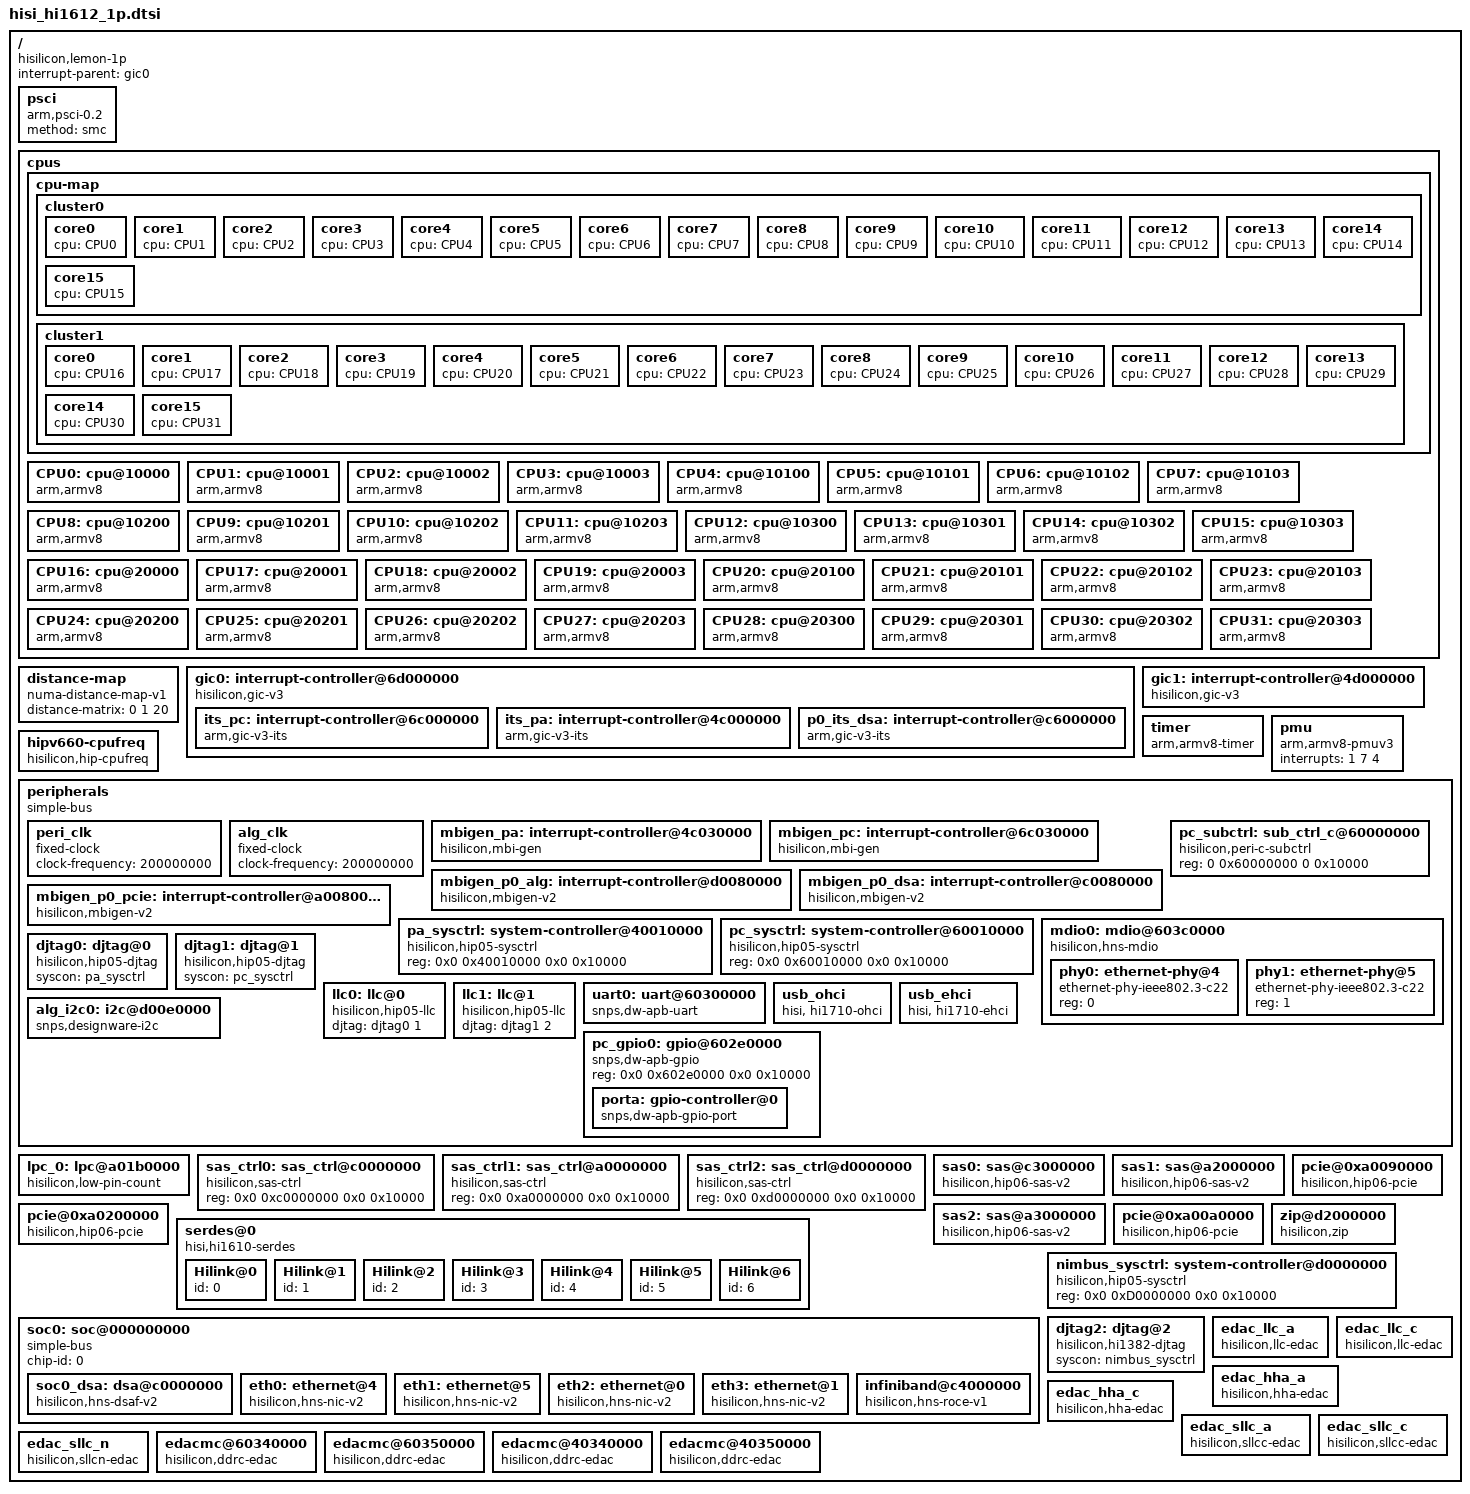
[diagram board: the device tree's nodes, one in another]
/**
 * dts file for IT lemon-1p Board(32cores)
 *
 * Copyright (C) 2014,2015 Hisilicon Ltd.
 *
 * This program is free software; you can redistribute it and/or modify
 * it under the terms of the GNU General Public License version 2 as
 * publishhed by the Free Software Foundation.
 *
 */

/ {
	#address-cells = <2>;
	#size-cells = <2>;
	compatible = "hisilicon,lemon-1p", "hisilicon,hi1612";
	interrupt-parent = <&gic0>;

	psci {
		compatible = "arm,psci-0.2";
		method = "smc";
	};

	cpus {
		#address-cells = <1>;
		#size-cells = <0>;

		cpu-map {
			cluster0 {
				core0 {
					cpu = <&CPU0>;
				};

				core1 {
					cpu = <&CPU1>;
				};

				core2 {
					cpu = <&CPU2>;
				};

				core3 {
					cpu = <&CPU3>;
				};

				core4 {
					cpu = <&CPU4>;
				};

				core5 {
					cpu = <&CPU5>;
				};

				core6 {
					cpu = <&CPU6>;
				};

				core7 {
					cpu = <&CPU7>;
				};

				core8 {
					cpu = <&CPU8>;
				};

				core9 {
					cpu = <&CPU9>;
				};

				core10 {
					cpu = <&CPU10>;
				};

				core11 {
					cpu = <&CPU11>;
				};

				core12 {
					cpu = <&CPU12>;
				};

				core13 {
					cpu = <&CPU13>;
				};

				core14 {
					cpu = <&CPU14>;
				};

				core15 {
					cpu = <&CPU15>;
				};
			};

			cluster1 {
				core0 {
					cpu = <&CPU16>;
				};

				core1 {
					cpu = <&CPU17>;
				};

				core2 {
					cpu = <&CPU18>;
				};

				core3 {
					cpu = <&CPU19>;
				};

				core4 {
					cpu = <&CPU20>;
				};

				core5 {
					cpu = <&CPU21>;
				};

				core6 {
					cpu = <&CPU22>;
				};

				core7 {
					cpu = <&CPU23>;
				};

				core8 {
					cpu = <&CPU24>;
				};

				core9 {
					cpu = <&CPU25>;
				};

				core10 {
					cpu = <&CPU26>;
				};

				core11 {
					cpu = <&CPU27>;
				};

				core12 {
					cpu = <&CPU28>;
				};

				core13 {
					cpu = <&CPU29>;
				};

				core14 {
					cpu = <&CPU30>;
				};

				core15 {
					cpu = <&CPU31>;
				};
			};
		};

		CPU0: cpu@10000 {
			device_type = "cpu";
			compatible = "arm,armv8";
			reg = <0x10000>;
			enable-method = "psci";
			numa-node-id = <0>;
		};

		CPU1: cpu@10001 {
			device_type = "cpu";
			compatible = "arm,armv8";
			reg = <0x10001>;
			enable-method = "psci";
			numa-node-id = <0>;
		};

		CPU2: cpu@10002 {
			device_type = "cpu";
			compatible = "arm,armv8";
			reg = <0x10002>;
			enable-method = "psci";
			numa-node-id = <0>;
		};

		CPU3: cpu@10003 {
			device_type = "cpu";
			compatible = "arm,armv8";
			reg = <0x10003>;
			enable-method = "psci";
			numa-node-id = <0>;
		};

		CPU4: cpu@10100 {
			device_type = "cpu";
			compatible = "arm,armv8";
			reg = <0x10100>;
			enable-method = "psci";
			numa-node-id = <0>;
		};

		CPU5: cpu@10101 {
			device_type = "cpu";
			compatible = "arm,armv8";
			reg = <0x10101>;
			enable-method = "psci";
			numa-node-id = <0>;
		};

		CPU6: cpu@10102 {
			device_type = "cpu";
			compatible = "arm,armv8";
			reg = <0x10102>;
			enable-method = "psci";
			numa-node-id = <0>;
		};

		CPU7: cpu@10103 {
			device_type = "cpu";
			compatible = "arm,armv8";
			reg = <0x10103>;
			enable-method = "psci";
			numa-node-id = <0>;
		};

		CPU8: cpu@10200 {
			device_type = "cpu";
			compatible = "arm,armv8";
			reg = <0x10200>;
			enable-method = "psci";
			numa-node-id = <0>;
		};

		CPU9: cpu@10201 {
			device_type = "cpu";
			compatible = "arm,armv8";
			reg = <0x10201>;
			enable-method = "psci";
			numa-node-id = <0>;
		};

		CPU10: cpu@10202 {
			device_type = "cpu";
			compatible = "arm,armv8";
			reg = <0x10202>;
			enable-method = "psci";
			numa-node-id = <0>;
		};

		CPU11: cpu@10203 {
			device_type = "cpu";
			compatible = "arm,armv8";
			reg = <0x10203>;
			enable-method = "psci";
			numa-node-id = <0>;
		};

		CPU12: cpu@10300 {
			device_type = "cpu";
			compatible = "arm,armv8";
			reg = <0x10300>;
			enable-method = "psci";
			numa-node-id = <0>;
		};

		CPU13: cpu@10301 {
			device_type = "cpu";
			compatible = "arm,armv8";
			reg = <0x10301>;
			enable-method = "psci";
			numa-node-id = <0>;
		};

		CPU14: cpu@10302 {
			device_type = "cpu";
			compatible = "arm,armv8";
			reg = <0x10302>;
			enable-method = "psci";
			numa-node-id = <0>;
		};

		CPU15: cpu@10303 {
			device_type = "cpu";
			compatible = "arm,armv8";
			reg = <0x10303>;
			enable-method = "psci";
			numa-node-id = <0>;
		};

		CPU16: cpu@20000 {
			device_type = "cpu";
			compatible = "arm,armv8";
			reg = <0x20000>;
			enable-method = "psci";
			numa-node-id = <1>;
		};

		CPU17: cpu@20001 {
			device_type = "cpu";
			compatible = "arm,armv8";
			reg = <0x20001>;
			enable-method = "psci";
			numa-node-id = <1>;
		};

		CPU18: cpu@20002 {
			device_type = "cpu";
			compatible = "arm,armv8";
			reg = <0x20002>;
			enable-method = "psci";
			numa-node-id = <1>;
		};

		CPU19: cpu@20003 {
			device_type = "cpu";
			compatible = "arm,armv8";
			reg = <0x20003>;
			enable-method = "psci";
			numa-node-id = <1>;
		};

		CPU20: cpu@20100 {
			device_type = "cpu";
			compatible = "arm,armv8";
			reg = <0x20100>;
			enable-method = "psci";
			numa-node-id = <1>;
		};

		CPU21: cpu@20101 {
			device_type = "cpu";
			compatible = "arm,armv8";
			reg = <0x20101>;
			enable-method = "psci";
			numa-node-id = <1>;
		};

		CPU22: cpu@20102 {
			device_type = "cpu";
			compatible = "arm,armv8";
			reg = <0x20102>;
			enable-method = "psci";
			numa-node-id = <1>;
		};

		CPU23: cpu@20103 {
			device_type = "cpu";
			compatible = "arm,armv8";
			reg = <0x20103>;
			enable-method = "psci";
			numa-node-id = <1>;
		};

		CPU24: cpu@20200 {
			device_type = "cpu";
			compatible = "arm,armv8";
			reg = <0x20200>;
			enable-method = "psci";
			numa-node-id = <1>;
		};

		CPU25: cpu@20201 {
			device_type = "cpu";
			compatible = "arm,armv8";
			reg = <0x20201>;
			enable-method = "psci";
			numa-node-id = <1>;
		};

		CPU26: cpu@20202 {
			device_type = "cpu";
			compatible = "arm,armv8";
			reg = <0x20202>;
			enable-method = "psci";
			numa-node-id = <1>;
		};

		CPU27: cpu@20203 {
			device_type = "cpu";
			compatible = "arm,armv8";
			reg = <0x20203>;
			enable-method = "psci";
			numa-node-id = <1>;
		};

		CPU28: cpu@20300 {
			device_type = "cpu";
			compatible = "arm,armv8";
			reg = <0x20300>;
			enable-method = "psci";
			numa-node-id = <1>;
		};

		CPU29: cpu@20301 {
			device_type = "cpu";
			compatible = "arm,armv8";
			reg = <0x20301>;
			enable-method = "psci";
			numa-node-id = <1>;
		};

		CPU30: cpu@20302 {
			device_type = "cpu";
			compatible = "arm,armv8";
			reg = <0x20302>;
			enable-method = "psci";
			numa-node-id = <1>;
		};

		CPU31: cpu@20303 {
			device_type = "cpu";
			compatible = "arm,armv8";
			reg = <0x20303>;
			enable-method = "psci";
			numa-node-id = <1>;
		};
	};

	distance-map {
		compatible = "numa-distance-map-v1";
		distance-matrix = <0 1 20>;
	};

	gic0: interrupt-controller@6d000000 {
		compatible = "hisilicon,gic-v3";
		#interrupt-cells = <3>;
		#address-cells = <2>;
		#size-cells = <2>;
		ranges;
		sgi-pending-fixup;
		status-clear-fixup;
		interrupt-controller;
		#redistributor-regions = <2>;
		redistributor-stride = <0x0 0x30000>;
		reg = <0x0 0x6d000000 0x0 0x10000>,	/* P0 GICD A*/
		      <0x0 0x6d100000 0x0 0x300000>,	/* P0 GICR A*/
		      <0x0 0x4d100000 0x0 0x300000>,	/* P0 GICR C*/
		      <0x0 0xfe000000 0 0x10000>,	/* GICC */
		      <0x0 0xfe010000 0 0x10000>,	/* GICH */
		      <0x0 0xfe020000 0 0x10000>;	/* GICV */

		interrupts = <1 9 0xff04>;

		its_pc: interrupt-controller@6c000000 {
			compatible = "arm,gic-v3-its";
			msi-controller;
			reg = <0x0 0x6c000000 0x0 0x1000000>;
		};

		its_pa: interrupt-controller@4c000000 {
			compatible = "arm,gic-v3-its";
			msi-controller;
			reg = <0x0 0x4c000000 0x0 0x1000000>;
		};

		p0_its_dsa: interrupt-controller@c6000000 {
			compatible = "arm,gic-v3-its";
			msi-controller;
			reg = <0x0 0xc6000000 0x0 0x1000000>;
		};
	};

	gic1: interrupt-controller@4d000000 {		/* P0 GICD C*/
		compatible = "hisilicon,gic-v3";
		#interrupt-cells = <3>;
		#address-cells = <2>;
		#size-cells = <2>;
		interrupt-controller;
		reg = <0x0 0x4d000000 0x0 0x10000>;
	};

	timer {
		compatible = "arm,armv8-timer";
		interrupts = <1 13 4>,
			     <1 14 4>,
			     <1 11 4>,
			     <1 10 4>;
		hisi,erratum-totem-v2;
	};

	pmu {
		compatible = "arm,armv8-pmuv3";
		interrupts = <1 7 4>;
	};

	hipv660-cpufreq {
		compatible = "hisilicon,hip-cpufreq";
		reg = <0x0 0x40010000 0x0 0x10000>,
		      <0x0 0x80000000 0x0 0x10000>,
		      <0x0 0xe0000000 0x0 0x10000>;
	};

	peripherals {
		compatible = "simple-bus";
		#address-cells = <2>;
		#size-cells = <2>;
		ranges = <0x0 0x0 0x0 0x0 0xfff 0xffffffff>;

		peri_clk: peri_clk {
			compatible = "fixed-clock";
			#clock-cells = <0>;
			clock-frequency = <200000000>;
		};

		alg_clk: alg_clk {
			compatible = "fixed-clock";
			#clock-cells = <0>;
			clock-frequency = <200000000>;
		};

		mbigen_pa: interrupt-controller@4c030000 {
			compatible = "hisilicon,mbi-gen";
			msi-parent = <&its_pa>;
			interrupt-controller;
			#interrupt-cells = <2>;
			reg = <0x0 0x4c030000 0x0 0x10000>;
		};

		mbigen_pc: interrupt-controller@6c030000 {
			compatible = "hisilicon,mbi-gen";
			msi-parent = <&its_pc>;
			interrupt-controller;
			#interrupt-cells = <2>;
			reg = <0x0 0x6c030000 0x0 0x10000>;
		};

		mbigen_p0_alg: interrupt-controller@d0080000 {
			compatible = "hisilicon,mbigen-v2";
			msi-parent = <&p0_its_dsa>;
			interrupt-controller;
			#interrupt-cells = <4>;
			reg = <0x0 0xd0080000 0x0 0x10000>;
		};

		mbigen_p0_dsa: interrupt-controller@c0080000 {
			compatible = "hisilicon,mbigen-v2";
			msi-parent = <&p0_its_dsa>;
			interrupt-controller;
			#interrupt-cells = <4>;
			reg = <0x0 0xc0080000 0x0 0x10000>;
		};

		mbigen_p0_pcie: interrupt-controller@a0080000 {
			compatible = "hisilicon,mbigen-v2";
			msi-parent = <&p0_its_dsa>;
			interrupt-controller;
			#interrupt-cells = <4>;
			reg = <0x0 0xa0080000 0x0 0x10000>;
		};

		pa_sysctrl: system-controller@40010000 {
			compatible = "hisilicon,hip05-sysctrl", "syscon";
			reg = <0x0 0x40010000 0x0 0x10000>;
		};

		pc_sysctrl: system-controller@60010000 {
			compatible = "hisilicon,hip05-sysctrl", "syscon";
			reg = <0x0 0x60010000 0x0 0x10000>;
		};

		pc_subctrl: sub_ctrl_c@60000000 {
			compatible = "hisilicon,peri-c-subctrl", "syscon";
			reg = <0 0x60000000 0 0x10000>;
		};

		mdio0: mdio@603c0000 {
			compatible = "hisilicon,hns-mdio";
			reg = <0x0 0x603c0000 0x0 0x1000>;
			subctrl_vbase = <&pc_subctrl>;
			#address-cells = <0x1>;
			#size-cells = <0x0>;

			phy0: ethernet-phy@4 {
				compatible = "ethernet-phy-ieee802.3-c22";
				reg = <0>;
			};
			phy1: ethernet-phy@5 {
				compatible = "ethernet-phy-ieee802.3-c22";
				reg = <1>;
			};

		};
		djtag0: djtag@0 {
			compatible = "hisilicon,hip05-djtag";
			syscon = <&pa_sysctrl>;
		};

		djtag1: djtag@1 {
			compatible = "hisilicon,hip05-djtag";
			syscon = <&pc_sysctrl>;
		};

		llc0: llc@0 {
			compatible = "hisilicon,hip05-llc";
			djtag = <&djtag0 1>;
		};

		llc1: llc@1 {
			compatible = "hisilicon,hip05-llc";
			djtag = <&djtag1 2>;
		};

		uart0: uart@60300000 {
			compatible = "snps,dw-apb-uart";
			reg = <0x0 0x60300000 0x0 0x10000>;
			interrupts = <0 317 4>;
			clocks = <&peri_clk>;
			clock-names = "apb_pclk";
			reg-shift = <2>;
		};

		usb_ohci {
			compatible = "hisi, hi1710-ohci", "generic-ohci";
			reg = <0x0 0xa7030000 0x0 0x10000>;
			interrupt-parent = <&mbigen_p0_pcie>;
			interrupts = <0x40080 2 64 5>;
			dma-coherent;
		};

		usb_ehci {
			compatible = "hisi, hi1710-ehci", "generic-ehci";
			reg = <0x0 0xa7020000 0x0 0x10000>;
			interrupt-parent = <&mbigen_p0_pcie>;
			interrupts = <0x40080 2 65 5>;
			dma-coherent;
		};

		alg_i2c0: i2c@d00e0000 {
			#address-cells = <1>;
			#size-cells = <0>;
			compatible = "snps,designware-i2c";
			interrupt-parent = <&mbigen_p0_alg>;
			reg = <0x0 0xd00e0000 0x0 0x10000>;
			interrupts = <0x40b0e 1 1 6>;
			i2c-sda-falling-time-ns = <913>;
			i2c-scl-falling-time-ns = <303>;
			i2c-sda-hold-time-ns = <0x9c2>;
			clocks = <&alg_clk>;
			clock-frequency = <100000>;
		};

		pc_gpio0: gpio@602e0000 {
			#address-cells = <1>;
			#size-cells = <0>;
			compatible = "snps,dw-apb-gpio";
			reg = <0x0 0x602e0000 0x0 0x10000>;

			porta: gpio-controller@0 {
				compatible = "snps,dw-apb-gpio-port";
				gpio-controller;
				#gpio-cells = <2>;
				snps,nr-gpios = <32>;
				reg = <0>;
				interrupt-controller;
				#interrupt-cells = <2>;
				interrupts = <0 312 4>;
			};
		};
	};

	lpc_0: lpc@a01b0000 {
		compatible = "hisilicon,low-pin-count";
		reg = <0x0 0xa01b0000 0x0 0x10000>,
		      <0x0 0xa0170000 0x0 0x10000>,
		      <0x0 0xa0100000 0x0 0x10000>;
	};

	sas_ctrl0: sas_ctrl@c0000000 {
			compatible = "hisilicon,sas-ctrl", "syscon";
			reg = <0x0 0xc0000000 0x0 0x10000>;
	};

	sas_ctrl1: sas_ctrl@a0000000 {
		compatible = "hisilicon,sas-ctrl", "syscon";
		reg = <0x0 0xa0000000 0x0 0x10000>;
	};

	sas_ctrl2: sas_ctrl@d0000000 {
		compatible = "hisilicon,sas-ctrl", "syscon";
		reg = <0x0 0xd0000000 0x0 0x10000>;
	};

	sas0: sas@c3000000 {
		compatible = "hisilicon,hip06-sas-v2";
		controller-id = <0>;
		reg = <0 0xc3000000 0 0x10000>;
		sas-addr = [50 01 88 20 16 00 00 00];
		hisilicon,sas-syscon = <&sas_ctrl0>;
		ctrl-reset-reg = <0xa60>;
		ctrl-reset-sts-reg = <0x5a30>;
		ctrl-clock-ena-reg = <0x338>;
		subctrl,sas-syscon = <&sas_ctrl2>;
		djtag = <&djtag2>;
		queue-count = <16>;
		phy-count = <8>;
		dma-coherent;
		interrupt-parent = <&mbigen_p0_dsa>;
		interrupts = <0x40900 128 0 1>,
		<0x40900 128 1 1>,
		<0x40900 128 2 1>,
		<0x40900 128 3 1>,
		<0x40900 128 4 1>,
		<0x40900 128 5 1>,
		<0x40900 128 6 1>,
		<0x40900 128 7 1>,
		<0x40900 128 8 1>,
		<0x40900 128 9 1>,
		<0x40900 128 10 1>,
		<0x40900 128 11 1>,
		<0x40900 128 12 1>,
		<0x40900 128 13 1>,
		<0x40900 128 14 1>,
		<0x40900 128 15 1>,
		<0x40900 128 16 1>,
		<0x40900 128 17 1>,
		<0x40900 128 18 1>,
		<0x40900 128 19 1>,
		<0x40900 128 20 1>,
		<0x40900 128 21 1>,
		<0x40900 128 22 1>,
		<0x40900 128 23 1>,
		<0x40900 128 24 1>,
		<0x40900 128 25 1>,
		<0x40900 128 26 1>,
		<0x40900 128 27 1>,
		<0x40900 128 28 1>,
		<0x40900 128 29 1>,
		<0x40900 128 30 1>,
		<0x40900 128 31 1>,
		<0x40900 128 32 1>,
		<0x40900 128 33 1>,
		<0x40900 128 34 1>,
		<0x40900 128 35 1>,
		<0x40900 128 36 1>,
		<0x40900 128 37 1>,
		<0x40900 128 38 1>,
		<0x40900 128 39 1>,
		<0x40900 128 40 1>,
		<0x40900 128 41 1>,
		<0x40900 128 42 1>,
		<0x40900 128 43 1>,
		<0x40900 128 44 1>,
		<0x40900 128 45 1>,
		<0x40900 128 46 1>,
		<0x40900 128 47 1>,
		<0x40900 128 48 1>,
		<0x40900 128 49 1>,
		<0x40900 128 50 1>,
		<0x40900 128 51 1>,
		<0x40900 128 52 1>,
		<0x40900 128 53 1>,
		<0x40900 128 54 1>,
		<0x40900 128 55 1>,
		<0x40900 128 56 1>,
		<0x40900 128 57 1>,
		<0x40900 128 58 1>,
		<0x40900 128 59 1>,
		<0x40900 128 60 1>,
		<0x40900 128 61 1>,
		<0x40900 128 62 1>,
		<0x40900 128 63 1>,
		<0x40900 128 64 1>,
		<0x40900 128 65 1>,
		<0x40900 128 66 1>,
		<0x40900 128 67 1>,
		<0x40900 128 68 1>,
		<0x40900 128 69 1>,
		<0x40900 128 70 1>,
		<0x40900 128 71 1>,
		<0x40900 128 72 1>,
		<0x40900 128 73 1>,
		<0x40900 128 74 1>,
		<0x40900 128 75 1>,
		<0x40900 128 76 1>,
		<0x40900 128 77 1>,
		<0x40900 128 78 1>,
		<0x40900 128 79 1>,
		<0x40900 128 80 1>,
		<0x40900 128 81 1>,
		<0x40900 128 82 1>,
		<0x40900 128 83 1>,
		<0x40900 128 84 1>,
		<0x40900 128 85 1>,
		<0x40900 128 86 1>,
		<0x40900 128 87 1>,
		<0x40900 128 88 1>,
		<0x40900 128 89 1>,
		<0x40900 128 90 1>,
		<0x40900 128 91 1>,
		<0x40900 128 92 1>,
		<0x40900 128 93 1>,
		<0x40900 128 94 1>,
		<0x40900 128 95 1>,
		<0x40900 128 25 5>,
		<0x40900 128 26 5>,
		<0x40900 128 27 5>,
		<0x40900 128 28 5>,
		<0x40900 128 29 5>,
		<0x40900 128 30 5>,
		<0x40900 128 31 5>,
		<0x40900 128 32 5>,
		<0x40900 128 33 5>,
		<0x40900 128 34 5>,
		<0x40900 128 35 5>,
		<0x40900 128 36 5>,
		<0x40900 128 37 5>,
		<0x40900 128 38 5>,
		<0x40900 128 39 5>,
		<0x40900 128 40 5>,
		<0x40900 128 41 5>,
		<0x40900 128 42 5>,
		<0x40900 128 43 5>,
		<0x40900 128 44 5>,
		<0x40900 128 45 5>,
		<0x40900 128 46 5>,
		<0x40900 128 47 5>,
		<0x40900 128 48 5>,
		<0x40900 128 49 5>,
		<0x40900 128 50 5>,
		<0x40900 128 51 5>,
		<0x40900 128 52 5>,
		<0x40900 128 53 5>,
		<0x40900 128 54 5>,
		<0x40900 128 55 5>,
		<0x40900 128 56 5>;
		status = "ok";
	};

	sas1: sas@a2000000 {
		compatible = "hisilicon,hip06-sas-v2";
		controller-id = <1>;
		reg = <0 0xa2000000 0 0x10000>;
		sas-addr = [50 01 88 20 16 00 00 00];
		hisilicon,sas-syscon = <&sas_ctrl1>;
		hip06-sas-v2-quirk-amt;
		ctrl-reset-reg = <0xa18>;
		ctrl-reset-sts-reg = <0x5a0c>;
		ctrl-clock-ena-reg = <0x318>;
		subctrl,sas-syscon = <&sas_ctrl2>;
		djtag = <&djtag2>;
		queue-count = <16>;
		phy-count = <8>;
		dma-coherent;
		interrupt-parent = <&mbigen_p0_pcie>;
		interrupts = <0x40000 128 0 1>,
		<0x40000 128 1 1>,
		<0x40000 128 2 1>,
		<0x40000 128 3 1>,
		<0x40000 128 4 1>,
		<0x40000 128 5 1>,
		<0x40000 128 6 1>,
		<0x40000 128 7 1>,
		<0x40000 128 8 1>,
		<0x40000 128 9 1>,
		<0x40000 128 10 1>,
		<0x40000 128 11 1>,
		<0x40000 128 12 1>,
		<0x40000 128 13 1>,
		<0x40000 128 14 1>,
		<0x40000 128 15 1>,
		<0x40000 128 16 1>,
		<0x40000 128 17 1>,
		<0x40000 128 18 1>,
		<0x40000 128 19 1>,
		<0x40000 128 20 1>,
		<0x40000 128 21 1>,
		<0x40000 128 22 1>,
		<0x40000 128 23 1>,
		<0x40000 128 24 1>,
		<0x40000 128 25 1>,
		<0x40000 128 26 1>,
		<0x40000 128 27 1>,
		<0x40000 128 28 1>,
		<0x40000 128 29 1>,
		<0x40000 128 30 1>,
		<0x40000 128 31 1>,
		<0x40000 128 32 1>,
		<0x40000 128 33 1>,
		<0x40000 128 34 1>,
		<0x40000 128 35 1>,
		<0x40000 128 36 1>,
		<0x40000 128 37 1>,
		<0x40000 128 38 1>,
		<0x40000 128 39 1>,
		<0x40000 128 40 1>,
		<0x40000 128 41 1>,
		<0x40000 128 42 1>,
		<0x40000 128 43 1>,
		<0x40000 128 44 1>,
		<0x40000 128 45 1>,
		<0x40000 128 46 1>,
		<0x40000 128 47 1>,
		<0x40000 128 48 1>,
		<0x40000 128 49 1>,
		<0x40000 128 50 1>,
		<0x40000 128 51 1>,
		<0x40000 128 52 1>,
		<0x40000 128 53 1>,
		<0x40000 128 54 1>,
		<0x40000 128 55 1>,
		<0x40000 128 56 1>,
		<0x40000 128 57 1>,
		<0x40000 128 58 1>,
		<0x40000 128 59 1>,
		<0x40000 128 60 1>,
		<0x40000 128 61 1>,
		<0x40000 128 62 1>,
		<0x40000 128 63 1>,
		<0x40000 128 64 1>,
		<0x40000 128 65 1>,
		<0x40000 128 66 1>,
		<0x40000 128 67 1>,
		<0x40000 128 68 1>,
		<0x40000 128 69 1>,
		<0x40000 128 70 1>,
		<0x40000 128 71 1>,
		<0x40000 128 72 1>,
		<0x40000 128 73 1>,
		<0x40000 128 74 1>,
		<0x40000 128 75 1>,
		<0x40000 128 76 1>,
		<0x40000 128 77 1>,
		<0x40000 128 78 1>,
		<0x40000 128 79 1>,
		<0x40000 128 80 1>,
		<0x40000 128 81 1>,
		<0x40000 128 82 1>,
		<0x40000 128 83 1>,
		<0x40000 128 84 1>,
		<0x40000 128 85 1>,
		<0x40000 128 86 1>,
		<0x40000 128 87 1>,
		<0x40000 128 88 1>,
		<0x40000 128 89 1>,
		<0x40000 128 90 1>,
		<0x40000 128 91 1>,
		<0x40000 128 92 1>,
		<0x40000 128 93 1>,
		<0x40000 128 94 1>,
		<0x40000 128 95 1>,
		<0x40000 128 0 5>,
		<0x40000 128 1 5>,
		<0x40000 128 2 5>,
		<0x40000 128 3 5>,
		<0x40000 128 4 5>,
		<0x40000 128 5 5>,
		<0x40000 128 6 5>,
		<0x40000 128 7 5>,
		<0x40000 128 8 5>,
		<0x40000 128 9 5>,
		<0x40000 128 10 5>,
		<0x40000 128 11 5>,
		<0x40000 128 12 5>,
		<0x40000 128 13 5>,
		<0x40000 128 14 5>,
		<0x40000 128 15 5>,
		<0x40000 128 16 5>,
		<0x40000 128 17 5>,
		<0x40000 128 18 5>,
		<0x40000 128 19 5>,
		<0x40000 128 20 5>,
		<0x40000 128 21 5>,
		<0x40000 128 22 5>,
		<0x40000 128 23 5>,
		<0x40000 128 24 5>,
		<0x40000 128 25 5>,
		<0x40000 128 26 5>,
		<0x40000 128 27 5>,
		<0x40000 128 28 5>,
		<0x40000 128 29 5>,
		<0x40000 128 31 5>,
		<0x40000 128 31 5>;
		status = "ok";
	};

	sas2: sas@a3000000 {
		compatible = "hisilicon,hip06-sas-v2";
		controller-id = <2>;
		reg = <0 0xa3000000 0 0x10000>;
		sas-addr = [50 01 88 20 16 00 00 00];
		hisilicon,sas-syscon = <&sas_ctrl1>;
		ctrl-reset-reg = <0xae0>;
		ctrl-reset-sts-reg = <0x5a70>;
		ctrl-clock-ena-reg = <0x3a8>;
		subctrl,sas-syscon = <&sas_ctrl2>;
		djtag = <&djtag2>;
		queue-count = <16>;
		phy-count = <8>;
		dma-coherent;
		interrupt-parent = <&mbigen_p0_pcie>;
		interrupts = <0x40040 128 0 2>,
		<0x40040 128 1 2>,
		<0x40040 128 2 2>,
		<0x40040 128 3 2>,
		<0x40040 128 4 2>,
		<0x40040 128 5 2>,
		<0x40040 128 6 2>,
		<0x40040 128 7 2>,
		<0x40040 128 8 2>,
		<0x40040 128 9 2>,
		<0x40040 128 10 2>,
		<0x40040 128 11 2>,
		<0x40040 128 12 2>,
		<0x40040 128 13 2>,
		<0x40040 128 14 2>,
		<0x40040 128 15 2>,
		<0x40040 128 16 2>,
		<0x40040 128 17 2>,
		<0x40040 128 18 2>,
		<0x40040 128 19 2>,
		<0x40040 128 20 2>,
		<0x40040 128 21 2>,
		<0x40040 128 22 2>,
		<0x40040 128 23 2>,
		<0x40040 128 24 2>,
		<0x40040 128 25 2>,
		<0x40040 128 26 2>,
		<0x40040 128 27 2>,
		<0x40040 128 28 2>,
		<0x40040 128 29 2>,
		<0x40040 128 30 2>,
		<0x40040 128 31 2>,
		<0x40040 128 32 2>,
		<0x40040 128 33 2>,
		<0x40040 128 34 2>,
		<0x40040 128 35 2>,
		<0x40040 128 36 2>,
		<0x40040 128 37 2>,
		<0x40040 128 38 2>,
		<0x40040 128 39 2>,
		<0x40040 128 40 2>,
		<0x40040 128 41 2>,
		<0x40040 128 42 2>,
		<0x40040 128 43 2>,
		<0x40040 128 44 2>,
		<0x40040 128 45 2>,
		<0x40040 128 46 2>,
		<0x40040 128 47 2>,
		<0x40040 128 48 2>,
		<0x40040 128 49 2>,
		<0x40040 128 50 2>,
		<0x40040 128 51 2>,
		<0x40040 128 52 2>,
		<0x40040 128 53 2>,
		<0x40040 128 54 2>,
		<0x40040 128 55 2>,
		<0x40040 128 56 2>,
		<0x40040 128 57 2>,
		<0x40040 128 58 2>,
		<0x40040 128 59 2>,
		<0x40040 128 60 2>,
		<0x40040 128 61 2>,
		<0x40040 128 62 2>,
		<0x40040 128 63 2>,
		<0x40040 128 64 2>,
		<0x40040 128 65 2>,
		<0x40040 128 66 2>,
		<0x40040 128 67 2>,
		<0x40040 128 68 2>,
		<0x40040 128 69 2>,
		<0x40040 128 70 2>,
		<0x40040 128 71 2>,
		<0x40040 128 72 2>,
		<0x40040 128 73 2>,
		<0x40040 128 74 2>,
		<0x40040 128 75 2>,
		<0x40040 128 76 2>,
		<0x40040 128 77 2>,
		<0x40040 128 78 2>,
		<0x40040 128 79 2>,
		<0x40040 128 80 2>,
		<0x40040 128 81 2>,
		<0x40040 128 82 2>,
		<0x40040 128 83 2>,
		<0x40040 128 84 2>,
		<0x40040 128 85 2>,
		<0x40040 128 86 2>,
		<0x40040 128 87 2>,
		<0x40040 128 88 2>,
		<0x40040 128 89 2>,
		<0x40040 128 90 2>,
		<0x40040 128 91 2>,
		<0x40040 128 92 2>,
		<0x40040 128 93 2>,
		<0x40040 128 94 2>,
		<0x40040 128 95 2>,
		<0x40040 128 32 5>,
		<0x40040 128 33 5>,
		<0x40040 128 34 5>,
		<0x40040 128 35 5>,
		<0x40040 128 36 5>,
		<0x40040 128 37 5>,
		<0x40040 128 38 5>,
		<0x40040 128 39 5>,
		<0x40040 128 40 5>,
		<0x40040 128 41 5>,
		<0x40040 128 42 5>,
		<0x40040 128 43 5>,
		<0x40040 128 44 5>,
		<0x40040 128 45 5>,
		<0x40040 128 46 5>,
		<0x40040 128 47 5>,
		<0x40040 128 48 5>,
		<0x40040 128 49 5>,
		<0x40040 128 50 5>,
		<0x40040 128 51 5>,
		<0x40040 128 52 5>,
		<0x40040 128 53 5>,
		<0x40040 128 54 5>,
		<0x40040 128 55 5>,
		<0x40040 128 56 5>,
		<0x40040 128 57 5>,
		<0x40040 128 58 5>,
		<0x40040 128 59 5>,
		<0x40040 128 60 5>,
		<0x40040 128 61 5>,
		<0x40040 128 62 5>,
		<0x40040 128 63 5>;
		status = "ok";
	};

	pcie@0xa0090000 {
		compatible = "hisilicon,hip06-pcie", "snps,dw-pcie";
		reg = <0 0xa0090000 0 0x10000>, <0 0xa0000000 0 0x10000>,
		      <0 0xa00c0000 0 0x10000>, <0 0xb7f00000 0 0x10000>;
		reg-names = "rc_dbi", "subctrl", "pcs", "config";
		bus-range = <0  31>;
		msi-parent = <&p0_its_dsa>;
		#address-cells = <3>;
		#size-cells = <2>;
		device_type = "pci";
		dma-coherent;
		ranges = <0x82000000 0 0xb0000000 0x0 0xb0000000 0 0x7f00000
			  0x01000000 0 0 0 0xb7f10000 0 0x10000>;
		num-lanes = <8>;
		port-id = <0>;
		interrupt-parent = <&mbigen_p0_pcie>;
		interrupts = <0x40085 10 70 5>;
		interrupt-names = "aer";
		#interrupt-cells = <1>;
		interrupt-map-mask = <0xf800 0 0 7>;
		interrupt-map = <0x0 0 0 1 &mbigen_p0_pcie 0x40085 10 74 5
				0x0 0 0 2 &mbigen_p0_pcie 0x40085 10 74 5
				0x0 0 0 3 &mbigen_p0_pcie 0x40085 10 74 5
				0x0 0 0 4 &mbigen_p0_pcie 0x40085 10 74 5>;
		linux,pci-domain = <0>;
		smmu_ro = <1>;
		status = "ok";
	};

	pcie@0xa0200000 {
		compatible = "hisilicon,hip06-pcie", "snps,dw-pcie";
		reg = <0 0xa0200000 0 0x10000>, <0 0xa0000000 0 0x10000>,
		      <0 0xa00d0000 0 0x10000>, <0 0xbff00000 0 0x10000>;
		reg-names = "rc_dbi", "subctrl", "pcs", "config";
		bus-range = <32  63>;
		msi-parent = <&p0_its_dsa>;

		#address-cells = <3>;
		#size-cells = <2>;
		device_type = "pci";
		dma-coherent;
		ranges = <0x82000000 0 0xb8000000 0x0 0xb8000000 0 0x7f00000
			  0x01000000 0 0 0 0xbff10000 0 0x10000>;
		num-lanes = <8>;
		port-id = <1>;
		interrupt-parent = <&mbigen_p0_pcie>;
		interrupts = <0x40086 11 80 5>;
		interrupt-names = "aer";
		#interrupt-cells = <1>;
		interrupt-map-mask = <0xf800 0 0 7>;
		interrupt-map = <0x0 0 0 1 &mbigen_p0_pcie 0x40086 11 85 5
				0x0 0 0 2 &mbigen_p0_pcie 0x40086 11 85 5
				0x0 0 0 3 &mbigen_p0_pcie 0x40086 11 85 5
				0x0 0 0 4 &mbigen_p0_pcie 0x40086 11 85 5>;
		linux,pci-domain = <0>;
		smmu_ro = <1>;
		status = "ok";
	};

	pcie@0xa00a0000 {
		compatible = "hisilicon,hip06-pcie", "snps,dw-pcie";
		reg = <0 0xa00a0000 0 0x10000>, <0 0xa0000000 0 0x10000>,
		      <0 0xa00e0000 0 0x10000>, <0 0xaff00000 0 0x10000>;
		reg-names = "rc_dbi", "subctrl", "pcs", "config";
		bus-range = <64 95>;
		msi-parent = <&p0_its_dsa>;
		#address-cells = <3>;
		#size-cells = <2>;
		device_type = "pci";
		dma-coherent;
		ranges = <0x02000000 0 0xa8000000 0x0 0xa8000000 0 0x7f00000
			  0x01000000 0 0 0 0xaff10000 0 0x10000>;
		num-lanes = <8>;
		port-id = <2>;
		interrupt-parent = <&mbigen_p0_pcie>;
		interrupts = <0x40087 10 91 5>;
		interrupt-names = "aer";
		#interrupt-cells = <1>;
		interrupt-map-mask = <0xf800 0 0 7>;
		interrupt-map = <0x0 0 0 1 &mbigen_p0_pcie 0x40087 10 95 5
				0x0 0 0 2 &mbigen_p0_pcie 0x40087 10 95 5
				0x0 0 0 3 &mbigen_p0_pcie 0x40087 10 95 5
				0x0 0 0 4 &mbigen_p0_pcie 0x40087 10 95 5>;
		linux,pci-domain = <0>;
		smmu_ro = <1>;
		status = "ok";
	};

	zip@d2000000 {
		compatible = "hisilicon,zip";
		interrupt-parent = <&mbigen_p0_dsa>;
		interrupts =
			<0x40a00 0x42 0x39 0x5>, <0x40a00 0x42 0x3a 0x5>,
			<0x40a00 0x42 0x3b 0x5>, <0x40a00 0x42 0x3c 0x5>,
			<0x40a00 0x42 0x3d 0x5>, <0x40a00 0x42 0x3e 0x5>,
			<0x40a00 0x42 0x3f 0x5>, <0x40a00 0x42 0x40 0x5>,
			<0x40a00 0x42 0x41 0x5>, <0x40a00 0x42 0x42 0x5>,
			<0x40a00 0x42 0x43 0x5>, <0x40a00 0x42 0x44 0x5>,
			<0x40a00 0x42 0x45 0x5>, <0x40a00 0x42 0x46 0x5>,
			<0x40a00 0x42 0x47 0x5>, <0x40a00 0x42 0x48 0x5>,
			<0x40a00 0x42 0x49 0x5>, <0x40a00 0x42 0x4a 0x5>,
			<0x40a00 0x42 0x4b 0x5>, <0x40a00 0x42 0x4c 0x5>,
			<0x40a00 0x42 0x4d 0x5>, <0x40a00 0x42 0x4e 0x5>,
			<0x40a00 0x42 0x4f 0x5>, <0x40a00 0x42 0x50 0x5>,
			<0x40a00 0x42 0x51 0x5>, <0x40a00 0x42 0x52 0x5>,
			<0x40a00 0x42 0x53 0x5>, <0x40a00 0x42 0x54 0x5>,
			<0x40a00 0x42 0x55 0x5>, <0x40a00 0x42 0x56 0x5>,
			<0x40a00 0x42 0x57 0x5>, <0x40a00 0x42 0x58 0x5>,
			<0x40a00 0x42 0x59 0x5>, <0x40a00 0x42 0x5a 0x5>,
			<0x40a00 0x42 0x5b 0x5>, <0x40a00 0x42 0x5c 0x5>;
	};

	serdes@0 {
		compatible = "hisi,hi1610-serdes";
		id = <0>;
		reg = 	<0x0 0xc0000000 0 0x10000>,
			<0x0 0xa0000000 0 0x10000>,
			<0x0 0xd0000000 0 0x10000>,
			<0x0 0xc2200000 0 0x40000>,
			<0x0 0xc2240000 0 0x40000>;
		reg-names = "sas_dsaf_base",
					"sas_pcie_base",
					"alg_hccs_base",
					"hilink34_base",
					"hilink34_sel_base";
		Hilink@0 {
			id = <0>;
		};
		Hilink@1 {
			id = <1>;
		};
		Hilink@2 {
			id = <2>;
		};
		Hilink@3 {
			id = <3>;
		};
		Hilink@4 {
			id = <4>;
		};
		Hilink@5 {
			id = <5>;
		};
		Hilink@6 {
			id = <6>;
		};
	};

	soc0: soc@000000000 {
		#address-cells = <2>;
		#size-cells = <2>;
		device_type = "soc";
		compatible = "simple-bus";
		ranges = <0x0 0x0 0x0 0x0 0x1 0x0>;
		chip-id = <0>;

		soc0_dsa: dsa@c0000000 {
			compatible = "hisilicon,hns-dsaf-v2";
			mode = "6port-16rss";
			phy-handle = <0 0 0 0 &phy0 &phy1 0 0>;
			reg = <0x0 0xC0000000 0x0 0x420000
					0x0 0xC2000000 0x0 0x300000
					0x0 0xc5000000 0x0 0x890000
					0x0 0xc7000000 0x0 0x60000
					0x0 0x78000010 0x0 0x100>;
			desc-num = <0x400>;
			buf-size = <0x1000>;
			m3-enable = <0>;
			media-type = "fiber", "fiber", "unknown", "unknown",
				"copper", "copper", "unknown", "unknown";

			interrupt-parent = <&mbigen_p0_dsa>;
			interrupts =
				<0x40800 409 0 5>,<0x40800 409 1 5>,
				<0x40800 409 2 5>,<0x40800 409 3 5>,
				<0x40800 409 4 5>,<0x40800 409 5 5>,
				<0x40800 409 6 5>,<0x40800 409 7 5>,
				<0x40800 409 8 5>,<0x40800 409 9 5>,
				<0x40800 409 10 5>,<0x40800 409 11 5>,
				<0x40800 409 12 5>,
				<0x40800 409 0 7>,<0x40800 409 1 7>,
				<0x40800 409 2 7>,<0x40800 409 3 7>,
				<0x40800 409 4 7>,<0x40800 409 5 7>,
				<0x40800 409 6 7>,<0x40800 409 7 7>,
				<0x40800 409 8 7>,<0x40800 409 9 7>,
				<0x40800 409 10 7>,<0x40800 409 11 7>,
				/* index 25/26/27 ring0 tx/rx/doorbell*/
				<0x40800 409 0 8>,<0x40800 409 1 8>,
				<0x40800 409 2 8>,<0x40800 409 3 8>,
				<0x40800 409 4 8>,<0x40800 409 5 8>,
				<0x40800 409 6 8>,<0x40800 409 7 8>,
				<0x40800 409 8 8>,<0x40800 409 9 8>,
				<0x40800 409 10 8>,<0x40800 409 11 8>,
				<0x40800 409 12 8>,<0x40800 409 13 8>,
				<0x40800 409 14 8>,<0x40800 409 15 8>,
				<0x40800 409 16 8>,<0x40800 409 17 8>,
				<0x40800 409 18 8>,<0x40800 409 19 8>,
				<0x40800 409 20 8>,<0x40800 409 21 8>,
				<0x40800 409 22 8>,<0x40800 409 23 8>,
				<0x40800 409 24 8>,<0x40800 409 25 8>,
				<0x40800 409 26 8>,<0x40800 409 27 8>,
				<0x40800 409 28 8>,<0x40800 409 29 8>,
				<0x40800 409 30 8>,<0x40800 409 31 8>,
				<0x40800 409 32 8>,<0x40800 409 33 8>,
				<0x40800 409 34 8>,<0x40800 409 35 8>,
				<0x40800 409 36 8>,<0x40800 409 37 8>,
				<0x40800 409 38 8>,<0x40800 409 39 8>,
				<0x40800 409 40 8>,<0x40800 409 41 8>,
				<0x40800 409 42 8>,<0x40800 409 43 8>,
				<0x40800 409 44 8>,<0x40800 409 45 8>,
				<0x40800 409 46 8>,<0x40800 409 47 8>,
				<0x40800 409 48 8>,<0x40800 409 49 8>,
				<0x40800 409 50 8>,<0x40800 409 51 8>,
				<0x40800 409 52 8>,<0x40800 409 53 8>,
				<0x40800 409 54 8>,<0x40800 409 55 8>,
				<0x40800 409 56 8>,<0x40800 409 57 8>,
				<0x40800 409 58 8>,<0x40800 409 59 8>,
				<0x40800 409 60 8>,<0x40800 409 61 8>,
				<0x40800 409 62 8>,<0x40800 409 63 8>,
				<0x40800 409 64 8>,<0x40800 409 65 8>,
				<0x40800 409 66 8>,<0x40800 409 67 8>,
				<0x40800 409 68 8>,<0x40800 409 69 8>,
				<0x40800 409 70 8>,<0x40800 409 71 8>,
				<0x40800 409 72 8>,<0x40800 409 73 8>,
				<0x40800 409 74 8>,<0x40800 409 75 8>,
				<0x40800 409 76 8>,<0x40800 409 77 8>,
				<0x40800 409 78 8>,<0x40800 409 79 8>,
				<0x40800 409 80 8>,<0x40800 409 81 8>,
				<0x40800 409 82 8>,<0x40800 409 83 8>,
				<0x40800 409 84 8>,<0x40800 409 85 8>,
				<0x40800 409 86 8>,<0x40800 409 87 8>,
				<0x40800 409 88 8>,<0x40800 409 89 8>,
				<0x40800 409 90 8>,<0x40800 409 91 8>,
				<0x40800 409 92 8>,<0x40800 409 93 8>,
				<0x40800 409 94 8>,<0x40800 409 95 8>,
				<0x40800 409 96 8>,<0x40800 409 97 8>,
				<0x40800 409 98 8>,<0x40800 409 99 8>,
				<0x40800 409 100 8>,<0x40800 409 101 8>,
				<0x40800 409 102 8>,<0x40800 409 103 8>,
				<0x40800 409 104 8>,<0x40800 409 105 8>,
				<0x40800 409 106 8>,<0x40800 409 107 8>,
				<0x40800 409 108 8>,<0x40800 409 109 8>,
				<0x40800 409 110 8>,<0x40800 409 111 8>,
				<0x40800 409 112 8>,<0x40800 409 113 8>,
				<0x40800 409 114 8>,<0x40800 409 115 8>,
				<0x40800 409 116 8>,<0x40800 409 117 8>,
				<0x40800 409 118 8>,<0x40800 409 119 8>,
				<0x40800 409 120 8>,<0x40800 409 121 8>,
				<0x40800 409 122 8>,<0x40800 409 123 8>,
				<0x40800 409 124 8>,<0x40800 409 125 8>,
				<0x40800 409 126 8>,<0x40800 409 127 8>,
				<0x40800 409 0 9>,<0x40800 409 1 9>,
				<0x40800 409 2 9>,<0x40800 409 3 9>,
				<0x40800 409 4 9>,<0x40800 409 5 9>,
				<0x40800 409 6 9>,<0x40800 409 7 9>,
				<0x40800 409 8 9>,<0x40800 409 9 9>,
				<0x40800 409 10 9>,<0x40800 409 11 9>,
				<0x40800 409 12 9>,<0x40800 409 13 9>,
				<0x40800 409 14 9>,<0x40800 409 15 9>,
				<0x40800 409 16 9>,<0x40800 409 17 9>,
				<0x40800 409 18 9>,<0x40800 409 19 9>,
				<0x40800 409 20 9>,<0x40800 409 21 9>,
				<0x40800 409 22 9>,<0x40800 409 23 9>,
				<0x40800 409 24 9>,<0x40800 409 25 9>,
				<0x40800 409 26 9>,<0x40800 409 27 9>,
				<0x40800 409 28 9>,<0x40800 409 29 9>,
				<0x40800 409 30 9>,<0x40800 409 31 9>,
				<0x40800 409 32 9>,<0x40800 409 33 9>,
				<0x40800 409 34 9>,<0x40800 409 35 9>,
				<0x40800 409 36 9>,<0x40800 409 37 9>,
				<0x40800 409 38 9>,<0x40800 409 39 9>,
				<0x40800 409 40 9>,<0x40800 409 41 9>,
				<0x40800 409 42 9>,<0x40800 409 43 9>,
				<0x40800 409 44 9>,<0x40800 409 45 9>,
				<0x40800 409 46 9>,<0x40800 409 47 9>,
				<0x40800 409 48 9>,<0x40800 409 49 9>,
				<0x40800 409 50 9>,<0x40800 409 51 9>,
				<0x40800 409 52 9>,<0x40800 409 53 9>,
				<0x40800 409 54 9>,<0x40800 409 55 9>,
				<0x40800 409 56 9>,<0x40800 409 57 9>,
				<0x40800 409 58 9>,<0x40800 409 59 9>,
				<0x40800 409 60 9>,<0x40800 409 61 9>,
				<0x40800 409 62 9>,<0x40800 409 63 9>,
				<0x40800 409 64 9>,<0x40800 409 65 9>,
				<0x40800 409 66 9>,<0x40800 409 67 9>,
				<0x40800 409 68 9>,<0x40800 409 69 9>,
				<0x40800 409 70 9>,<0x40800 409 71 9>,
				<0x40800 409 72 9>,<0x40800 409 73 9>,
				<0x40800 409 74 9>,<0x40800 409 75 9>,
				<0x40800 409 76 9>,<0x40800 409 77 9>,
				<0x40800 409 78 9>,<0x40800 409 79 9>,
				<0x40800 409 80 9>,<0x40800 409 81 9>,
				<0x40800 409 82 9>,<0x40800 409 83 9>,
				<0x40800 409 84 9>,<0x40800 409 85 9>,
				<0x40800 409 86 9>,<0x40800 409 87 9>,
				<0x40800 409 88 9>,<0x40800 409 89 9>,
				<0x40800 409 90 9>,<0x40800 409 91 9>,
				<0x40800 409 92 9>,<0x40800 409 93 9>,
				<0x40800 409 94 9>,<0x40800 409 95 9>,
				<0x40800 409 96 9>,<0x40800 409 97 9>,
				<0x40800 409 98 9>,<0x40800 409 99 9>,
				<0x40800 409 100 9>,<0x40800 409 101 9>,
				<0x40800 409 102 9>,<0x40800 409 103 9>,
				<0x40800 409 104 9>,<0x40800 409 105 9>,
				<0x40800 409 106 9>,<0x40800 409 107 9>,
				<0x40800 409 108 9>,<0x40800 409 109 9>,
				<0x40800 409 110 9>,<0x40800 409 111 9>,
				<0x40800 409 112 9>,<0x40800 409 113 9>,
				<0x40800 409 114 9>,<0x40800 409 115 9>,
				<0x40800 409 116 9>,<0x40800 409 117 9>,
				<0x40800 409 118 9>,<0x40800 409 119 9>,
				<0x40800 409 120 9>,<0x40800 409 121 9>,
				<0x40800 409 122 9>,<0x40800 409 123 9>,
				<0x40800 409 124 9>,<0x40800 409 125 9>,
				<0x40800 409 126 9>,<0x40800 409 127 9>,
				<0x40800 409 0 10>,<0x40800 409 1 10>,
				<0x40800 409 2 10>,<0x40800 409 3 10>,
				<0x40800 409 4 10>,<0x40800 409 5 10>,
				<0x40800 409 6 10>,<0x40800 409 7 10>,
				<0x40800 409 8 10>,<0x40800 409 9 10>,
				<0x40800 409 10 10>,<0x40800 409 11 10>,
				<0x40800 409 12 10>,<0x40800 409 13 10>,
				<0x40800 409 14 10>,<0x40800 409 15 10>,
				<0x40800 409 16 10>,<0x40800 409 17 10>,
				<0x40800 409 18 10>,<0x40800 409 19 10>,
				<0x40800 409 20 10>,<0x40800 409 21 10>,
				<0x40800 409 22 10>,<0x40800 409 23 10>,
				<0x40800 409 24 10>,<0x40800 409 25 10>,
				<0x40800 409 26 10>,<0x40800 409 27 10>,
				<0x40800 409 28 10>,<0x40800 409 29 10>,
				<0x40800 409 30 10>,<0x40800 409 31 10>,
				<0x40800 409 32 10>,<0x40800 409 33 10>,
				<0x40800 409 34 10>,<0x40800 409 35 10>,
				<0x40800 409 36 10>,<0x40800 409 37 10>,
				<0x40800 409 38 10>,<0x40800 409 39 10>,
				<0x40800 409 40 10>,<0x40800 409 41 10>,
				<0x40800 409 42 10>,<0x40800 409 43 10>,
				<0x40800 409 44 10>,<0x40800 409 45 10>,
				<0x40800 409 46 10>,<0x40800 409 47 10>,
				<0x40800 409 48 10>,<0x40800 409 49 10>,
				<0x40800 409 50 10>,<0x40800 409 51 10>,
				<0x40800 409 52 10>,<0x40800 409 53 10>,
				<0x40800 409 54 10>,<0x40800 409 55 10>,
				<0x40800 409 56 10>,<0x40800 409 57 10>,
				<0x40800 409 58 10>,<0x40800 409 59 10>,
				<0x40800 409 60 10>,<0x40800 409 61 10>,
				<0x40800 409 62 10>,<0x40800 409 63 10>,
				<0x40800 409 64 10>,<0x40800 409 65 10>,
				<0x40800 409 66 10>,<0x40800 409 67 10>,
				<0x40800 409 68 10>,<0x40800 409 69 10>,
				<0x40800 409 70 10>,<0x40800 409 71 10>,
				<0x40800 409 72 10>,<0x40800 409 73 10>,
				<0x40800 409 74 10>,<0x40800 409 75 10>,
				<0x40800 409 76 10>,<0x40800 409 77 10>,
				<0x40800 409 78 10>,<0x40800 409 79 10>,
				<0x40800 409 80 10>,<0x40800 409 81 10>,
				<0x40800 409 82 10>,<0x40800 409 83 10>,
				<0x40800 409 84 10>,<0x40800 409 85 10>,
				<0x40800 409 86 10>,<0x40800 409 87 10>,
				<0x40800 409 88 10>,<0x40800 409 89 10>,
				<0x40800 409 90 10>,<0x40800 409 91 10>,
				<0x40800 409 92 10>,<0x40800 409 93 10>,
				<0x40800 409 94 10>,<0x40800 409 95 10>,
				<0x40800 409 96 10>,<0x40800 409 97 10>,
				<0x40800 409 98 10>,<0x40800 409 99 10>,
				<0x40800 409 100 10>,<0x40800 409 101 10>,
				<0x40800 409 102 10>,<0x40800 409 103 10>,
				<0x40800 409 104 10>,<0x40800 409 105 10>,
				<0x40800 409 106 10>,<0x40800 409 107 10>,
				<0x40800 409 108 10>,<0x40800 409 109 10>,
				<0x40800 409 110 10>,<0x40800 409 111 10>,
				<0x40800 409 112 10>,<0x40800 409 113 10>,
				<0x40800 409 114 10>,<0x40800 409 115 10>,
				<0x40800 409 116 10>,<0x40800 409 117 10>,
				<0x40800 409 118 10>,<0x40800 409 119 10>,
				<0x40800 409 120 10>,<0x40800 409 121 10>,
				<0x40800 409 122 10>,<0x40800 409 123 10>,
				<0x40800 409 124 10>,<0x40800 409 125 10>,
				<0x40800 409 126 10>,<0x40800 409 127 10>,
				/* index = 409 debug0 tx/rx */
				<0x40b1c 9 0 6>,<0x40b1c 9 1 6>,
				<0x40b1c 9 2 6>,<0x40b1c 9 3 6>,
				<0x40b1c 9 4 6>,<0x40b1c 9 5 6>,
				<0x40b1c 9 6 6>,<0x40b1c 9 7 6>,
				<0x40b1c 9 8 6>,
				/* index = 418 debug1 tx/rx */
				<0x40b1d 9 9 6>,<0x40b1d 9 10 6>,
				<0x40b1d 9 11 6>,<0x40b1d 9 12 6>,
				<0x40b1d 9 13 6>,<0x40b1d 9 14 6>,
				<0x40b1d 9 15 6>,<0x40b1d 9 16 6>,
				<0x40b1d 9 17 6>,
				/* xbar int index=427 */
				<0x40b1f 18 51 6>,<0x40b1f 18 52 6>,
				<0x40b1f 18 53 6>,<0x40b1f 18 54 6>,
				<0x40b1f 18 55 6>,<0x40b1f 18 56 6>,
				<0x40b1f 18 57 6>,<0x40b1f 18 58 6>,
				<0x40b1f 18 59 6>,<0x40b1f 18 60 6>,
				<0x40b1f 18 61 6>,<0x40b1f 18 62 6>,
				<0x40b1f 18 63 6>,<0x40b1f 18 64 6>,
				<0x40b1f 18 65 6>,<0x40b1f 18 66 6>,
				<0x40b1f 18 67 6>,<0x40b1f 18 68 6>,
				<0x40881 12 13 5>, /* GE0 int index=445 */
				<0x40881 12 14 5>,
				<0x40881 12 15 5>,
				<0x40881 12 16 5>,
				<0x40881 12 17 5>,
				<0x40881 12 18 5>,
				<0x40881 12 19 5>, /* XGE0 int index=451 */
				<0x40881 12 20 5>,
				<0x40881 12 21 5>,
				<0x40881 12 22 5>,
				<0x40881 12 23 5>,
				<0x40881 12 24 5>;
			dma-coherent;
		};

		eth0:ethernet@4 {
			compatible = "hisilicon,hns-nic-v2";
			ae-handle = <&soc0_dsa>;
			port-id = <6>;
			local-mac-address = [00 00 00 01 00 58];
			dma-coherent;
		};

		eth1:ethernet@5 {
			compatible = "hisilicon,hns-nic-v2";
			ae-handle = <&soc0_dsa>;
			port-id = <7>;
			local-mac-address = [00 00 00 01 00 59];
			dma-coherent;
		};

		eth2:ethernet@0 {
			compatible = "hisilicon,hns-nic-v2";
			ae-handle = <&soc0_dsa>;
			port-id = <2>;
			local-mac-address = [00 00 00 01 00 5a];
			dma-coherent;
		};

		eth3:ethernet@1 {
			compatible = "hisilicon,hns-nic-v2";
			ae-handle = <&soc0_dsa>;
			port-id = <3>;
			local-mac-address = [00 00 00 01 00 5b];
			dma-coherent;
		};
		infiniband@c4000000 {
			compatible = "hisilicon,hns-roce-v1";
			reg = <0x0 0xc4000000 0x0 0x100000>;
			dma-coherent;
			eth-handle = <&eth2 &eth3>;
			dsaf-handle = <&soc0_dsa>;
			#address-cells = <2>;
			#size-cells = <2>;
			interrupt-parent = <&mbigen_p0_dsa>;
			interrupts = <0x40B1E 34 18 6>,
					<0x40B1E 34 19 6>,
					<0x40B1E 34 20 6>,
					<0x40B1E 34 21 6>,
					<0x40B1E 34 22 6>,
					<0x40B1E 34 23 6>,
					<0x40B1E 34 24 6>,
					<0x40B1E 34 25 6>,
					<0x40B1E 34 26 6>,
					<0x40B1E 34 27 6>,
					<0x40B1E 34 28 6>,
					<0x40B1E 34 29 6>,
					<0x40B1E 34 30 6>,
					<0x40B1E 34 31 6>,
					<0x40B1E 34 32 6>,
					<0x40B1E 34 33 6>,
					<0x40B1E 34 34 6>,
					<0x40B1E 34 35 6>,
					<0x40B1E 34 36 6>,
					<0x40B1E 34 37 6>,
					<0x40B1E 34 38 6>,
					<0x40B1E 34 39 6>,
					<0x40B1E 34 40 6>,
					<0x40B1E 34 41 6>,
					<0x40B1E 34 42 6>,
					<0x40B1E 34 43 6>,
					<0x40B1E 34 44 6>,
					<0x40B1E 34 45 6>,
					<0x40B1E 34 46 6>,
					<0x40B1E 34 47 6>,
					<0x40B1E 34 48 6>,
					<0x40B1E 34 49 6>,
					<0x40B1E 34 50 6>,
					<0x40B1E 34 81 6>;
			interrupt-names = "hns-roce-comp-0",
					"hns-roce-comp-1",
					"hns-roce-comp-2",
					"hns-roce-comp-3",
					"hns-roce-comp-4",
					"hns-roce-comp-5",
					"hns-roce-comp-6",
					"hns-roce-comp-7",
					"hns-roce-comp-8",
					"hns-roce-comp-9",
					"hns-roce-comp-10",
					"hns-roce-comp-11",
					"hns-roce-comp-12",
					"hns-roce-comp-13",
					"hns-roce-comp-14",
					"hns-roce-comp-15",
					"hns-roce-comp-16",
					"hns-roce-comp-17",
					"hns-roce-comp-18",
					"hns-roce-comp-19",
					"hns-roce-comp-20",
					"hns-roce-comp-21",
					"hns-roce-comp-22",
					"hns-roce-comp-23",
					"hns-roce-comp-24",
					"hns-roce-comp-25",
					"hns-roce-comp-26",
					"hns-roce-comp-27",
					"hns-roce-comp-28",
					"hns-roce-comp-29",
					"hns-roce-comp-30",
					"hns-roce-comp-31",
					"hns-roce-async",
					"hns-roce-common";
		};
	};

	nimbus_sysctrl: system-controller@d0000000 {
		compatible = "hisilicon,hip05-sysctrl", "syscon";
		reg = <0x0 0xD0000000 0x0 0x10000>;
	};

	djtag2: djtag@2 {
		compatible = "hisilicon,hi1382-djtag";
		syscon = <&nimbus_sysctrl>;
	};

	edac_llc_a {
		compatible = "hisilicon,llc-edac";
		reg = <0x0 0x40010000 0x0 0x10000>;
		interrupt-parent = <&mbigen_pa>;
		interrupts =	<141 4>,
				<142 4>,
				<143 4>,
				<144 4>;
		djtag = <&djtag0>;
	};

	edac_llc_c {
		compatible = "hisilicon,llc-edac";
		reg = <0x0 0x60010000 0x0 0x10000>;
		interrupt-parent = <&mbigen_pc>;
		interrupts =	<141 4>,
				<142 4>,
				<143 4>,
				<144 4>;
		djtag = <&djtag1>;
	};

	edac_hha_a {
		compatible = "hisilicon,hha-edac";
		reg = <0x0 0x40010000 0x0 0x10000>;
		interrupt-parent = <&mbigen_pa>;
		interrupts =	<147 4>,
				<148 4>;
		djtag = <&djtag0>;
	};

	edac_hha_c {
		compatible = "hisilicon,hha-edac";
		reg = <0x0 0x60010000 0x0 0x10000>;
		interrupt-parent = <&mbigen_pc>;
		interrupts =	<147 4>,
				<148 4>;
		djtag = <&djtag1>;
	};

	edac_sllc_a {
		compatible = "hisilicon,sllcc-edac";
		reg = <0x0 0x40000000 0x0 0x10000>;
		interrupt-parent = <&mbigen_pa>;
		interrupts =	<172 4>,
				<173 4>,
				<174 4>,
				<175 4>;
		djtag = <&djtag0>;
	};

	edac_sllc_c {
		compatible = "hisilicon,sllcc-edac";
		reg = <0x0 0x60000000 0x0 0x10000>;
		interrupt-parent = <&mbigen_pc>;
		interrupts =	<172 4>,
				<173 4>,
				<174 4>,
				<175 4>;
		djtag = <&djtag1>;
	};

	edac_sllc_n  {
		compatible = "hisilicon,sllcn-edac";
		reg = <0x0 0xD0000000 0x0 0x10000>;
		interrupt-parent = <&mbigen_p0_alg>;
		interrupts =	<0x40b1a 15 14 6>,
				<0x40b1a 15 15 6>,
				<0x40b1a 15 16 6>,
				<0x40b1a 15 17 6>,
				<0x40b1a 15 18 6>,
				<0x40b1a 15 19 6>,
				<0x40b1a 15 20 6>,
				<0x40b1a 15 21 6>,
				<0x40b1a 15 22 6>,
				<0x40b1a 15 23 6>,
				<0x40b1a 15 24 6>,
				<0x40b1a 15 25 6>,
				<0x40b1a 15 26 6>,
				<0x40b1a 15 27 6>,
				<0x40b1a 15 28 6>;
		djtag = <&djtag2>;
	};

	edacmc@60340000 {
		compatible = "hisilicon,ddrc-edac";
		reg = <0x0 0x60340000 0x0 0x10000>;
		interrupts =	<0 296 4>,
				<0 297 4>;
	};

	edacmc@60350000 {
		compatible = "hisilicon,ddrc-edac";
		reg = <0x0 0x60350000 0x0 0x10000>;
		interrupts =	<0 298 4>,
				<0 299 4>;
	};

	edacmc@40340000 {
		compatible = "hisilicon,ddrc-edac";
		reg = <0x0 0x40340000 0x0 0x10000>;
		interrupts =	<0 168 4>,
				<0 169 4>;
	};

	edacmc@40350000 {
		compatible = "hisilicon,ddrc-edac";
		reg = <0x0 0x40350000 0x0 0x10000>;
		interrupts =	<0 170 4>,
				<0 171 4>;
	};
};
